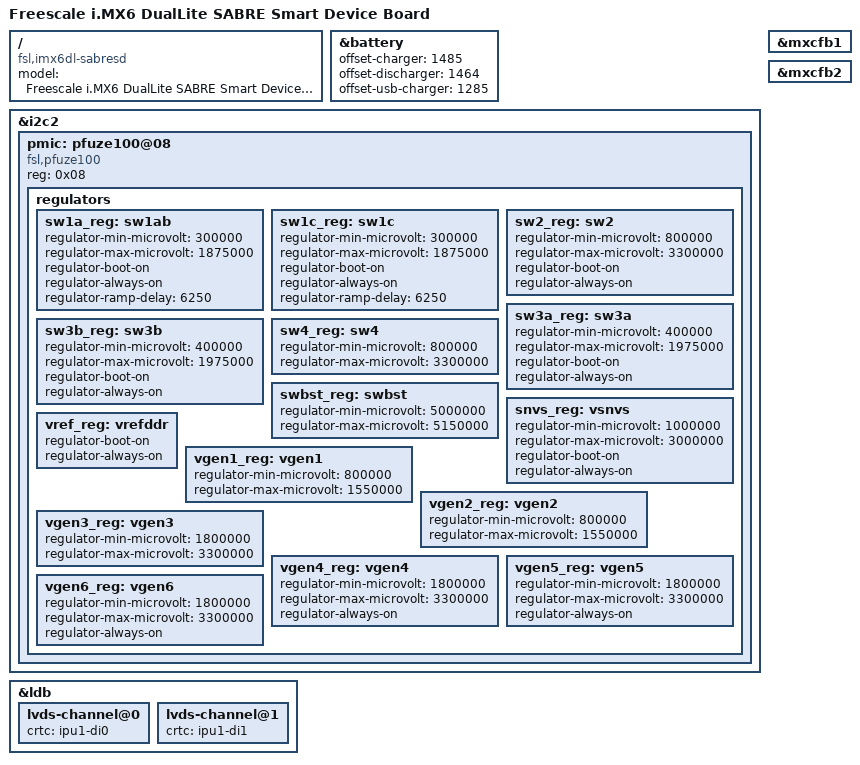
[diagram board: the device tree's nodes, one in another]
/*
 * Copyright (C) 2013 Freescale Semiconductor, Inc.
 *
 * This program is free software; you can redistribute it and/or modify
 * it under the terms of the GNU General Public License version 2 as
 * published by the Free Software Foundation.
 */

/dts-v1/;

#include "imx6dl.dtsi"
#include "imx6qdl-sabresd.dtsi"

/ {
	model = "Freescale i.MX6 DualLite SABRE Smart Device Board";
	compatible = "fsl,imx6dl-sabresd", "fsl,imx6dl";
};

&battery {
	offset-charger = <1485>;
	offset-discharger = <1464>;
	offset-usb-charger = <1285>;
};

&i2c2 {
	pmic: pfuze100@08 {
		compatible = "fsl,pfuze100";
		reg = <0x08>;

		regulators {
			sw1a_reg: sw1ab {
				regulator-min-microvolt = <300000>;
				regulator-max-microvolt = <1875000>;
				regulator-boot-on;
				regulator-always-on;
				regulator-ramp-delay = <6250>;
			};

			sw1c_reg: sw1c {
				regulator-min-microvolt = <300000>;
				regulator-max-microvolt = <1875000>;
				regulator-boot-on;
				regulator-always-on;
				regulator-ramp-delay = <6250>;
			};

			sw2_reg: sw2 {
				regulator-min-microvolt = <800000>;
				regulator-max-microvolt = <3300000>;
				regulator-boot-on;
				regulator-always-on;
			};

			sw3a_reg: sw3a {
				regulator-min-microvolt = <400000>;
				regulator-max-microvolt = <1975000>;
				regulator-boot-on;
				regulator-always-on;
			};

			sw3b_reg: sw3b {
				regulator-min-microvolt = <400000>;
				regulator-max-microvolt = <1975000>;
				regulator-boot-on;
				regulator-always-on;
			};

			sw4_reg: sw4 {
				regulator-min-microvolt = <800000>;
				regulator-max-microvolt = <3300000>;
			};

			swbst_reg: swbst {
				regulator-min-microvolt = <5000000>;
				regulator-max-microvolt = <5150000>;
			};

			snvs_reg: vsnvs {
				regulator-min-microvolt = <1000000>;
				regulator-max-microvolt = <3000000>;
				regulator-boot-on;
				regulator-always-on;
			};

			vref_reg: vrefddr {
				regulator-boot-on;
				regulator-always-on;
			};

			vgen1_reg: vgen1 {
				regulator-min-microvolt = <800000>;
				regulator-max-microvolt = <1550000>;
			};

			vgen2_reg: vgen2 {
				regulator-min-microvolt = <800000>;
				regulator-max-microvolt = <1550000>;
			};

			vgen3_reg: vgen3 {
				regulator-min-microvolt = <1800000>;
				regulator-max-microvolt = <3300000>;
			};

			vgen4_reg: vgen4 {
				regulator-min-microvolt = <1800000>;
				regulator-max-microvolt = <3300000>;
				regulator-always-on;
			};

			vgen5_reg: vgen5 {
				regulator-min-microvolt = <1800000>;
				regulator-max-microvolt = <3300000>;
				regulator-always-on;
			};

			vgen6_reg: vgen6 {
				regulator-min-microvolt = <1800000>;
				regulator-max-microvolt = <3300000>;
				regulator-always-on;
			};
		};
	};
};

&ldb {
	lvds-channel@0 {
		crtc = "ipu1-di0";
	};

	lvds-channel@1 {
		crtc = "ipu1-di1";
	};
};

&mxcfb1 {
	status = "okay";
};

&mxcfb2 {
	status = "okay";
};
